# STM32MP21_CA35 register map
File version: 0.4
CPU: CM33 r0p1, little endian, MPU, FPU, vendor SysTick, 8 interrupt priority bits
Registers are 32-bit, read-write, reset 0x0 unless marked. A register's access mark holds for its fields unless they carry their own. Offsets are from the block's base; [hi:lo] are bit positions; lines under a group give offsets from that group; {n}, {i} and the like mark numbered series.

## DDRDBG — DDRDBG address block description
Base 0x48050000
Same registers: DDRDBG_S 0x58050000
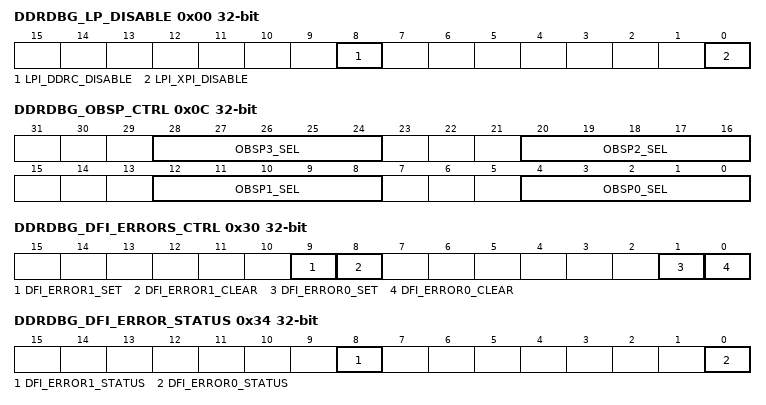
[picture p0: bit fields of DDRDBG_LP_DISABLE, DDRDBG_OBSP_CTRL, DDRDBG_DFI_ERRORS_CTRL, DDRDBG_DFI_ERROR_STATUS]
0x00 DDRDBG_LP_DISABLE — DDRDBG low-power disable register
  [8] LPI_DDRC_DISABLE
    0=No effect; 1=Disable automatic clock gating of DDRC when idle
  [0] LPI_XPI_DISABLE
    0=No effect; 1=Disable automatic clock gating of XPIs when idle
0x04 DDRDBG_BYPASS_PCLKEN
  [0] ENABLE
    0=No effect; 1=The DDRPHYC Bypass_Pclken is active
0x08 DDRDBG_DDRC_AUTO_SR_DELAY reset 0x20
  [7:0] DELAY_CYCLES — Number of delay cycles to wait before to gate down the DDRC clock when in auto self-refresh
0x0C DDRDBG_OBSP_CTRL — DDRDBG OBSP control register
  [8n+4:8n] OBSP{n}_SEL (n=0..3) — Selects which of the input observable signal is forwarded to the HDP on selectable observability line {n}.
0x10 DDRDBG_FRAC_PLL_LOCK
  [0] LOCK
    0=No effect; 1=PLL lock, direct copy of ddrss_pll2_lock
0x14 DDRDBG_DTO_OUTPUT
  [0] DTO — the DDRPHYC PLL lock can be observed in this register.
    0=No effect; 1=DDRPHYC DTO output is stored in this register
0x30 DDRDBG_DFI_ERRORS_CTRL — DDRDBG DFI error control register
  [9] DFI_ERROR1_SET
    0=No effect; 1=Trigger the interrupt linked with dfi_error
  [8] DFI_ERROR1_CLEAR
    0=No effect; 1=Clear the interrupt linked with dfi_error1
  [1] DFI_ERROR0_SET
    0=No effect; 1=Trigger the interrupt linked with dfi_error0
  [0] DFI_ERROR0_CLEAR
    0=No effect; 1=Clear the interrupt linked with dfi_error0
0x34 DDRDBG_DFI_ERROR_STATUS
  [8] DFI_ERROR1_STATUS — Status bit for dfi_error1
    0=No effect; 1=Clear the interrupt linked with dfi_error1
  [0] DFI_ERROR0_STATUS — Status bit for dfi_error0
    0=No effect; 1=Clear the interrupt linked with dfi_error0
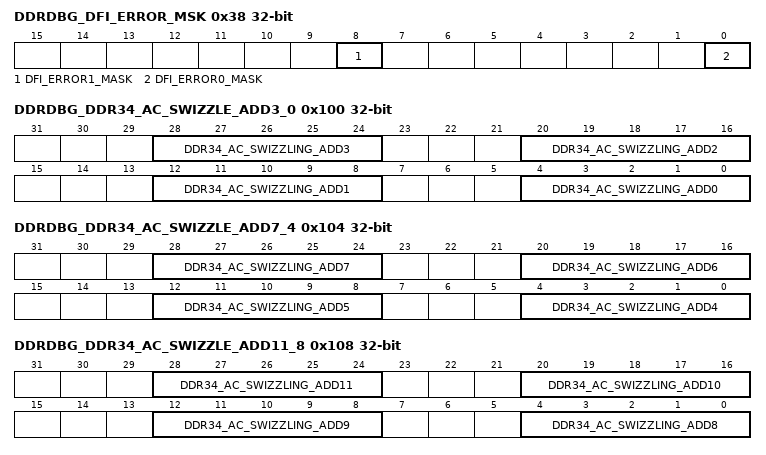
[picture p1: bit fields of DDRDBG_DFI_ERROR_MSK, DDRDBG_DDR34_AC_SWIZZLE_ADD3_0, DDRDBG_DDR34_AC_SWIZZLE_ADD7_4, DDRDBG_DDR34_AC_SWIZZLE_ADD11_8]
0x38 DDRDBG_DFI_ERROR_MSK — DDRDBG DFI error mask register
  [8] DFI_ERROR1_MASK
    0=No effect; 1=Interrupt linked to dfi_error1 is masked
  [0] DFI_ERROR0_MASK
    0=No effect; 1=Interrupt linked to dfi_error0 is masked
0x100 DDRDBG_DDR34_AC_SWIZZLE_ADD3_0
  [8n+4:8n] DDR34_AC_SWIZZLING_ADD{n} (n=0..3) — Remapping input bit on add{n} DDRPHYC input
0x104 DDRDBG_DDR34_AC_SWIZZLE_ADD7_4
  [8n-28:8n-32] DDR34_AC_SWIZZLING_ADD{n} (n=4..7) — Remapping input bit on add{n} DDRPHYC input
0x108 DDRDBG_DDR34_AC_SWIZZLE_ADD11_8
  [8n-60:8n-64] DDR34_AC_SWIZZLING_ADD{n} (n=8..11) — Remapping input bit on add{n} DDRPHYC input
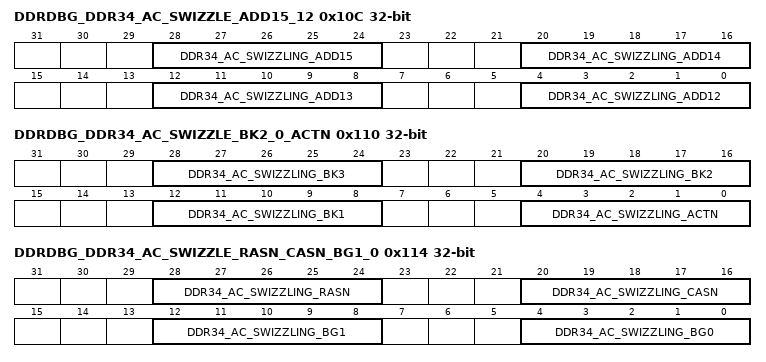
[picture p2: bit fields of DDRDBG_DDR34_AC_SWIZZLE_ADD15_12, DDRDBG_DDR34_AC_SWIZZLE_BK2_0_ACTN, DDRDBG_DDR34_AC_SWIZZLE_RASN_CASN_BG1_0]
0x10C DDRDBG_DDR34_AC_SWIZZLE_ADD15_12
  [8n-92:8n-96] DDR34_AC_SWIZZLING_ADD{n} (n=12..15) — Remapping input bit on add{n} DDRPHYC input
0x110 DDRDBG_DDR34_AC_SWIZZLE_BK2_0_ACTN
  [28:24] DDR34_AC_SWIZZLING_BK3 — Remapping input bit on bk3 DDRPHYC input
  [20:16] DDR34_AC_SWIZZLING_BK2 — Remapping input bit on bk2 DDRPHYC input
  [12:8] DDR34_AC_SWIZZLING_BK1 — Remapping input bit on bk1 DDRPHYC input
  [4:0] DDR34_AC_SWIZZLING_ACTN — Remapping input bit on actn DDRPHYC input
0x114 DDRDBG_DDR34_AC_SWIZZLE_RASN_CASN_BG1_0
  [28:24] DDR34_AC_SWIZZLING_RASN — Remapping input bit on rasn DDRPHYC input
  [20:16] DDR34_AC_SWIZZLING_CASN — Remapping input bit on casn DDRPHYC input
  [12:8] DDR34_AC_SWIZZLING_BG1 — Remapping input bit on bg1 DDRPHYC input
  [4:0] DDR34_AC_SWIZZLING_BG0 — Remapping input bit on bg0 DDRPHYC input
0x118 DDRDBG_DDR34_AC_SWIZZLE_WEN
  [4:0] DDR34_AC_SWIZZLING_WEN — Remapping input bit on wen DDRPHYC input

## GICH — GICH address block description
Base 0x4AC40000
Same registers: GICH_S 0x5AC40000
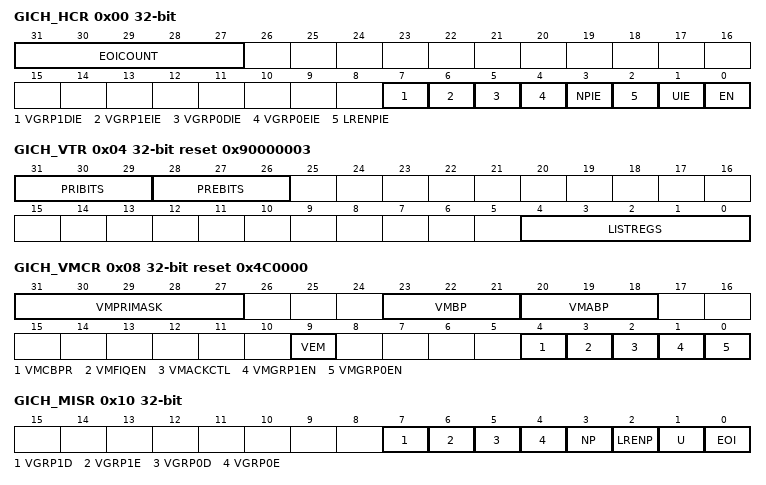
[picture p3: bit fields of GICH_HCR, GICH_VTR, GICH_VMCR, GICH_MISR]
0x00 GICH_HCR — GICH hypervisor control register
  [31:27] EOICOUNT — End-of-interrupt counter
  [7] VGRP1DIE — Virtual machine disable group 1 interrupt enable
  [6] VGRP1EIE — Virtual machine enable group 1 interrupt enable
  [5] VGRP0DIE — Virtual machine disable group 0 interrupt enable
  [4] VGRP0EIE — Virtual machine enable group 0interrupt enable
  [3] NPIE — No pending interrupt enable
  [2] LRENPIE — List register entry not present interrupt enable
  [1] UIE — Underflow interrupt enable.
  [0] EN — Global enable bit for the virtual CPU interface
0x04 GICH_VTR ro reset 0x90000003 — GICH VGIC type register
  [31:29] PRIBITS — Priority bits
  [28:26] PREBITS — Preemption bits
  [4:0] LISTREGS — List registers
0x08 GICH_VMCR reset 0x4C0000 — GICH virtual machine control register
  [31:27] VMPRIMASK — Alias of GICV_PMR.
  [23:21] VMBP — Alias of GICV_BPR.
  [20:18] VMABP — Alias of GICV_ABPR.
  [9] VEM — Alias of GICV_CTLR.
  [4] VMCBPR — Alias of GICV_CTLR.
  [3] VMFIQEN — Alias of GICV_CTLR.
  [2] VMACKCTL — Alias of GICV_CTLR.
  [1] VMGRP1EN — Alias of GICV_CTLR.
  [0] VMGRP0EN — Alias of GICV_CTLR.
0x10 GICH_MISR ro — GICH maintenance interrupt status register
  [7] VGRP1D — Disabled group 1 maintenance interrupt
  [6] VGRP1E — Enabled group 1 maintenance interrupt
  [5] VGRP0D — Disabled group 0 maintenance interrupt
  [4] VGRP0E — Enabled group 0 maintenance interrupt
  [3] NP — No pending maintenance interrupt
  [2] LRENP — List register entry not present maintenance interrupt
  [1] U — Underflow maintenance interrupt
  [0] EOI — End of interrupt maintenance interrupt
0x20 GICH_EISR0 ro (reset mask 0xF) — GICH end of interrupt status register
  [31:0] EISR0 — End of interrupt status
0x30 GICH_ELSR0 ro reset 0xF (reset mask 0xF) — GICH empty list status register
  [31:0] ELSR0 — Empty list status
0xF0 GICH_APR0 — GICH active priority register
  [31:0] APR0 — Active priority
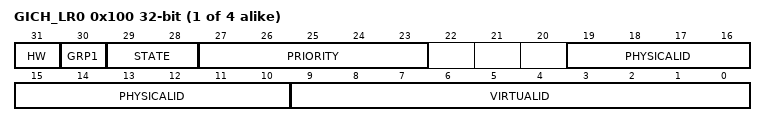
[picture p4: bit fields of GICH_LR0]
{0x100+4i} GICH_LR{i} (i=0..3) — GICH list register {i}
  [31] HW — Hardware interrupt
  [30] GRP1 — This bit indicates whether this virtual interrupt is a group 1 virtual interrupt.
  [29:28] STATE — State of the interrupt
  [27:23] PRIORITY — Priority of the interrupt
  [19:10] PHYSICALID
  [9:0] VIRTUALID
